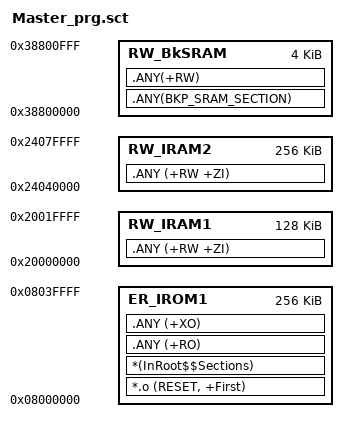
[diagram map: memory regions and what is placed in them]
; *************************************************************
; *** Scatter-Loading Description File generated by uVision ***
; *************************************************************

LR_IROM1 0x08000000 0x00040000  {    ; load region size_region
  ER_IROM1 0x08000000 0x00040000  {  ; load address = execution address
   *.o (RESET, +First)
   *(InRoot$$Sections)
   .ANY (+RO)
   .ANY (+XO)
  }
  RW_IRAM1 0x20000000 0x00020000  {  ; RW data
   .ANY (+RW +ZI)
  }
  RW_IRAM2 0x24040000 0x00040000  {
   .ANY (+RW +ZI)
  }
  RW_BkSRAM 0x38800000 0x1000     {  ;bkSRAM
   .ANY(BKP_SRAM_SECTION)  
   .ANY(+RW)   
  }
}

